# ADC12_3 register map
Vendor: Texas Instruments
Peripheral module from a debugger description file (folder msp430).
Registers are 16-bit, read-write, reset 0x0 unless marked. A register's access mark holds for its fields unless they carry their own. Offsets are as the file gives them; lines under a group give offsets from that group; [hi:lo] are bit positions; {n}, {i} and the like mark numbered series; 'fields as' and 'values as' point back to an identical list; <NAME> marks a mode.

## ADC12
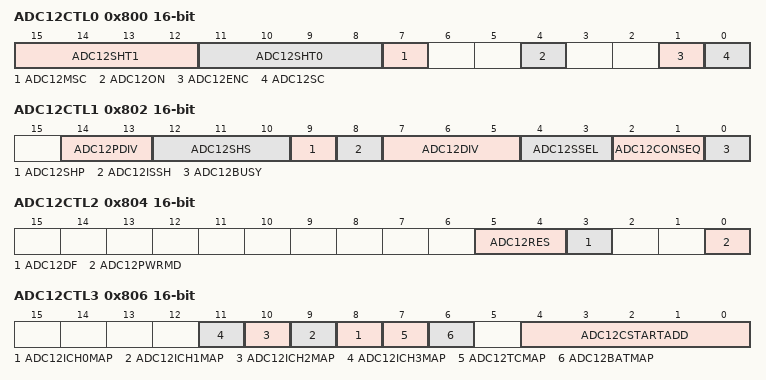
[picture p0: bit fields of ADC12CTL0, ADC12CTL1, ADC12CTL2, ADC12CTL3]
0x800 ADC12CTL0 — ADC12 B Control 0
  [15:12] ADC12SHT1 — ADC12 Sample Hold 1 Select Bit: 0
    {v}=ADC12 Sample Hold 1 Select Bit: {v} (v=0..15)
  [11:8] ADC12SHT0 — ADC12 Sample Hold 0 Select Bit: 0
    {v}=ADC12 Sample Hold 0 Select Bit: {v} (v=0..15)
  [7] ADC12MSC — ADC12 Multiple SampleConversion
  [4] ADC12ON — ADC12 On/enable
  [1] ADC12ENC — ADC12 Enable Conversion
  [0] ADC12SC — ADC12 Start Conversion
0x802 ADC12CTL1 — ADC12 B Control 1
  [14:13] ADC12PDIV — ADC12 Predivider Bit: 0
    {v}=ADC12 Clock predivider Select {v} (v=0..3)
  [12:10] ADC12SHS — ADC12 Sample/Hold Source Bit: 0
    {v}=ADC12 Sample/Hold Source: {v} (v=0..7)
  [9] ADC12SHP — ADC12 Sample/Hold Pulse Mode
  [8] ADC12ISSH — ADC12 Invert Sample Hold Signal
  [7:5] ADC12DIV — ADC12 Clock Divider Select Bit: 0
    {v}=ADC12 Clock Divider Select: {v} (v=0..7)
  [4:3] ADC12SSEL — ADC12 Clock Source Select Bit: 0
    {v}=ADC12 Clock Source Select: {v} (v=0..3)
  [2:1] ADC12CONSEQ — ADC12 Conversion Sequence Select Bit: 0
    {v}=ADC12 Conversion Sequence Select: {v} (v=0..3)
  [0] ADC12BUSY
0x804 ADC12CTL2 — ADC12 B Control 2
  [5:4] ADC12RES — ADC12 Resolution Bit: 0
    0=ADC12+ Resolution : 8 Bit; 1=ADC12+ Resolution : 10 Bit; 2=ADC12+ Resolution : 12 Bit; 3=ADC12+ Resolution : reserved
  [3] ADC12DF — ADC12 Data Format
  [0] ADC12PWRMD — ADC12 Power Mode
0x806 ADC12CTL3 — ADC12 B Control 3
  [n+8] ADC12ICH{n}MAP (n=0..3) — ADC12 Internal Channel {n} select
  [7] ADC12TCMAP — ADC12 Internal TempSensor select
  [6] ADC12BATMAP — ADC12 Internal AVCC/2 select
  [4:0] ADC12CSTARTADD — ADC12 Conversion Start Address Bit: 0
    {v}=ADC12 Conversion Start Address: {v} (v=0..31)
0x808 ADC12LO access not given reset not defined — ADC12 B Window Comparator High Threshold
0x80A ADC12HI access not given reset not defined — ADC12 B Window Comparator High Threshold
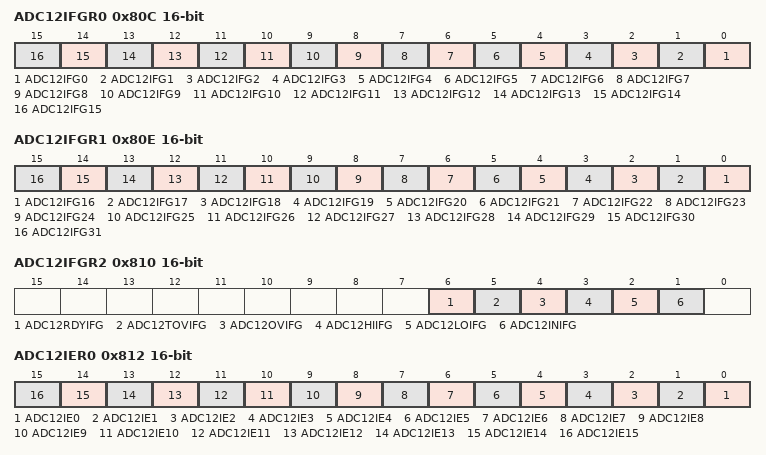
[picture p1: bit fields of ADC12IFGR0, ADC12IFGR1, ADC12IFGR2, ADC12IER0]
0x80C ADC12IFGR0 — ADC12 B Interrupt Flag 0
  [n] ADC12IFG{n} (n=0..15) — ADC12 Memory {n} Interrupt Flag
0x80E ADC12IFGR1 — ADC12 B Interrupt Flag 1
  [n-16] ADC12IFG{n} (n=16..31) — ADC12 Memory {n} Interrupt Flag
0x810 ADC12IFGR2 — ADC12 B Interrupt Flag 2
  [6] ADC12RDYIFG — ADC12 local buffered reference ready interrupt Flag
  [5] ADC12TOVIFG — ADC12 Timer Overflow interrupt Flag
  [4] ADC12OVIFG — ADC12 ADC12MEMx Overflow interrupt Flag
  [3] ADC12HIIFG — ADC12 Interrupt Flag for upper threshold of the Window comparator
  [2] ADC12LOIFG — ADC12 Interrupt Flag for lower threshold of the Window comparator
  [1] ADC12INIFG — ADC12 Interrupt Flag for the inside of window of the Window comparator
0x812 ADC12IER0 — ADC12 B Interrupt Enable 0
  [n] ADC12IE{n} (n=0..15) — ADC12 Memory {n} Interrupt Enable
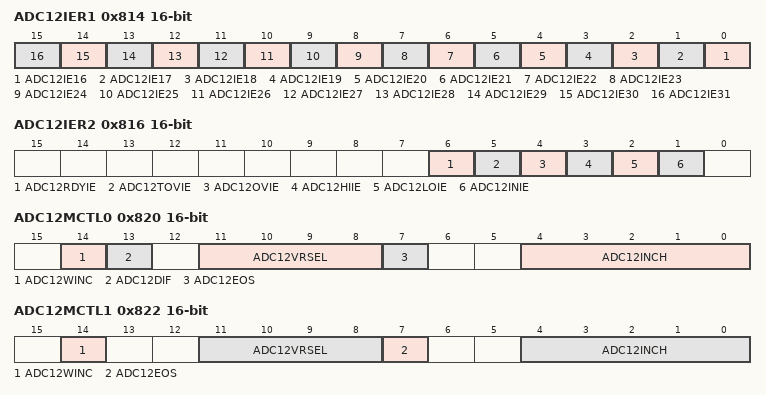
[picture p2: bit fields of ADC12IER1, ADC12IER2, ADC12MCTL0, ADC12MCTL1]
0x814 ADC12IER1 — ADC12 B Interrupt Enable 1
  [n-16] ADC12IE{n} (n=16..31) — ADC12 Memory {n} Interrupt Enable
0x816 ADC12IER2 — ADC12 B Interrupt Enable 2
  [6] ADC12RDYIE — ADC12 local buffered reference ready interrupt enable
  [5] ADC12TOVIE — ADC12 Timer Overflow interrupt enable
  [4] ADC12OVIE — ADC12 ADC12MEMx Overflow interrupt enable
  [3] ADC12HIIE — ADC12 Interrupt enable for upper threshold of the Window comparator
  [2] ADC12LOIE — ADC12 Interrupt enable for lower threshold of the Window comparator
  [1] ADC12INIE — ADC12 Interrupt enable for the inside of window of the Window comparator
0x818 ADC12IV access not given reset not defined — ADC12 B Interrupt Vector Word
0x820 ADC12MCTL0 — ADC12 Memory Control 0
  [14] ADC12WINC — ADC12 Comparator window enable
  [13] ADC12DIF — ADC12 Differential mode (only for even Registers)
  [11:8] ADC12VRSEL — ADC12 VR Select Bit 0
    {v}=ADC12 Select Reference {v} (v=0..15)
  [7] ADC12EOS — ADC12 End of Sequence
  [4:0] ADC12INCH — ADC12 Input Channel Select Bit 0
    {v}=ADC12 Input Channel {v} (v=0..31)
0x822 ADC12MCTL1 — ADC12 Memory Control 1
  [14] ADC12WINC — ADC12 Comparator window enable
  [11:8] ADC12VRSEL — ADC12 VR Select Bit 0
    {v}=ADC12 Select Reference {v} (v=0..15)
  [7] ADC12EOS — ADC12 End of Sequence
  [4:0] ADC12INCH — ADC12 Input Channel Select Bit 0
    {v}=ADC12 Input Channel {v} (v=0..31)
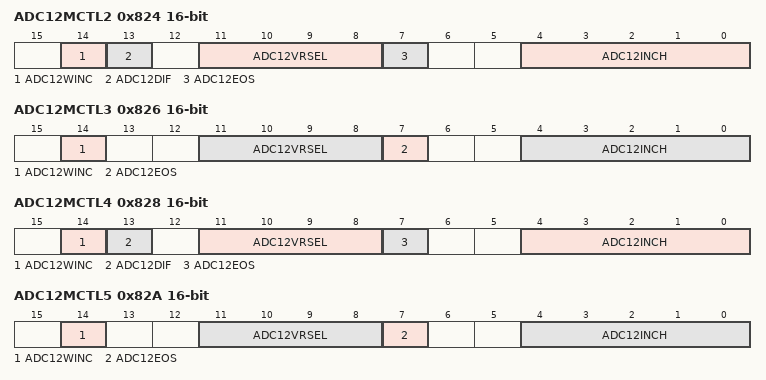
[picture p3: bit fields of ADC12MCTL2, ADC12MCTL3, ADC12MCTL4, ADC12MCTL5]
0x824 ADC12MCTL2 — ADC12 Memory Control 2
  fields as ADC12MCTL0
0x826 ADC12MCTL3 — ADC12 Memory Control 3
  fields as ADC12MCTL1
0x828 ADC12MCTL4 — ADC12 Memory Control 4
  fields as ADC12MCTL0
0x82A ADC12MCTL5 — ADC12 Memory Control 5
  fields as ADC12MCTL1
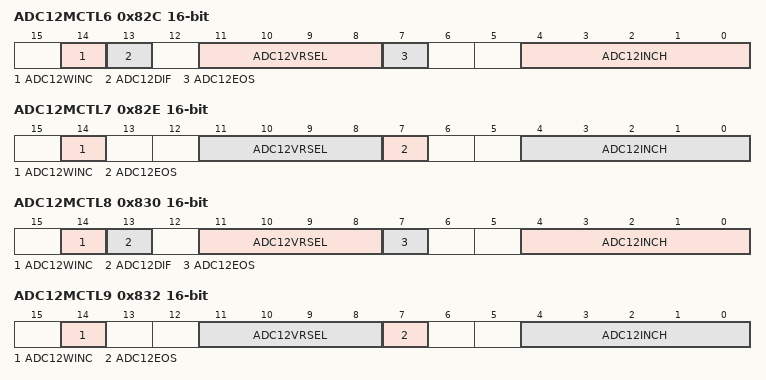
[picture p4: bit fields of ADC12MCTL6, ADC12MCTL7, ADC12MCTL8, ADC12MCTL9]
0x82C ADC12MCTL6 — ADC12 Memory Control 6
  fields as ADC12MCTL0
0x82E ADC12MCTL7 — ADC12 Memory Control 7
  fields as ADC12MCTL1
0x830 ADC12MCTL8 — ADC12 Memory Control 8
  fields as ADC12MCTL0
0x832 ADC12MCTL9 — ADC12 Memory Control 9
  fields as ADC12MCTL1
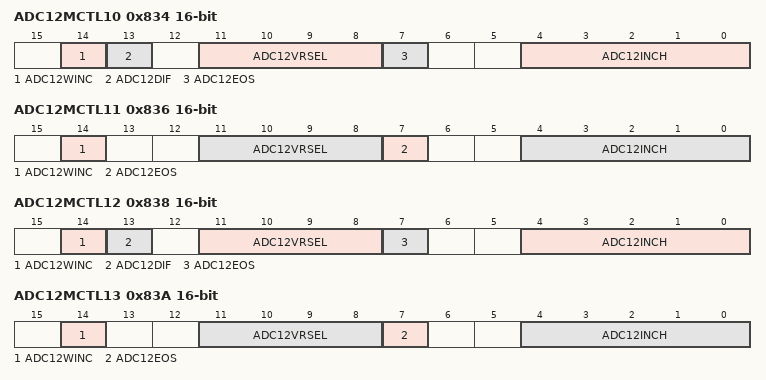
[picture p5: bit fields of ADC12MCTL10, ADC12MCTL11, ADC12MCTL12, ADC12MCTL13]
0x834 ADC12MCTL10 — ADC12 Memory Control 10
  fields as ADC12MCTL0
0x836 ADC12MCTL11 — ADC12 Memory Control 11
  fields as ADC12MCTL1
0x838 ADC12MCTL12 — ADC12 Memory Control 12
  fields as ADC12MCTL0
0x83A ADC12MCTL13 — ADC12 Memory Control 13
  fields as ADC12MCTL1
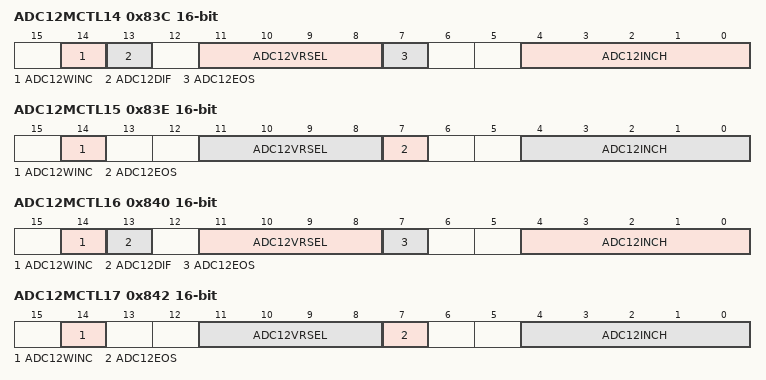
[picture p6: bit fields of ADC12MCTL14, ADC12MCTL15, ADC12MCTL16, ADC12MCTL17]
0x83C ADC12MCTL14 — ADC12 Memory Control 14
  fields as ADC12MCTL0
0x83E ADC12MCTL15 — ADC12 Memory Control 15
  fields as ADC12MCTL1
0x840 ADC12MCTL16 — ADC12 Memory Control 16
  fields as ADC12MCTL0
0x842 ADC12MCTL17 — ADC12 Memory Control 17
  fields as ADC12MCTL1
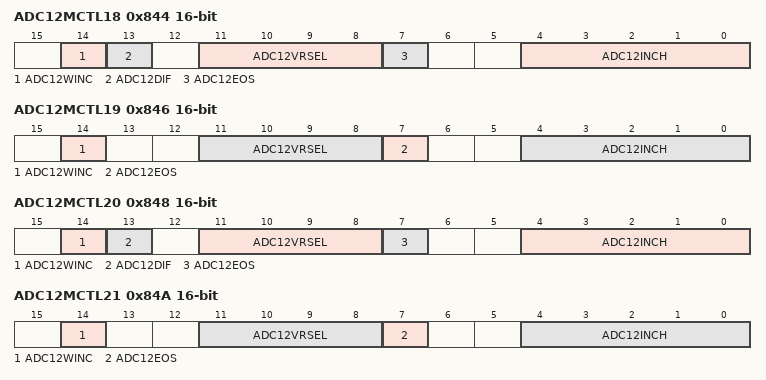
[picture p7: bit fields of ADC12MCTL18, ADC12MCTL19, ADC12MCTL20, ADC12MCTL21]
0x844 ADC12MCTL18 — ADC12 Memory Control 18
  fields as ADC12MCTL0
0x846 ADC12MCTL19 — ADC12 Memory Control 19
  fields as ADC12MCTL1
0x848 ADC12MCTL20 — ADC12 Memory Control 20
  fields as ADC12MCTL0
0x84A ADC12MCTL21 — ADC12 Memory Control 21
  fields as ADC12MCTL1
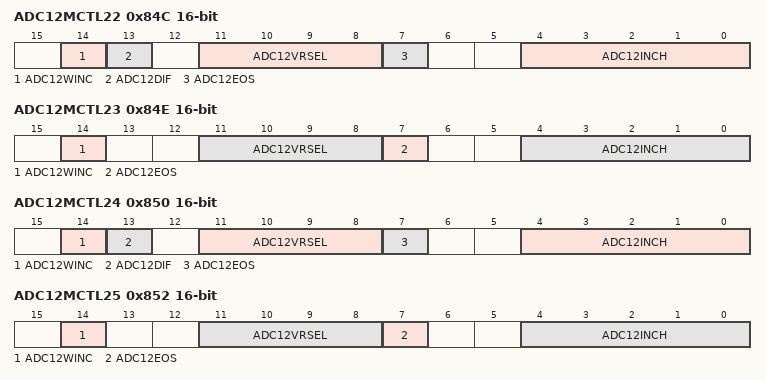
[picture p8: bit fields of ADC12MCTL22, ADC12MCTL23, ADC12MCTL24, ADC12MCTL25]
0x84C ADC12MCTL22 — ADC12 Memory Control 22
  fields as ADC12MCTL0
0x84E ADC12MCTL23 — ADC12 Memory Control 23
  fields as ADC12MCTL1
0x850 ADC12MCTL24 — ADC12 Memory Control 24
  fields as ADC12MCTL0
0x852 ADC12MCTL25 — ADC12 Memory Control 25
  fields as ADC12MCTL1
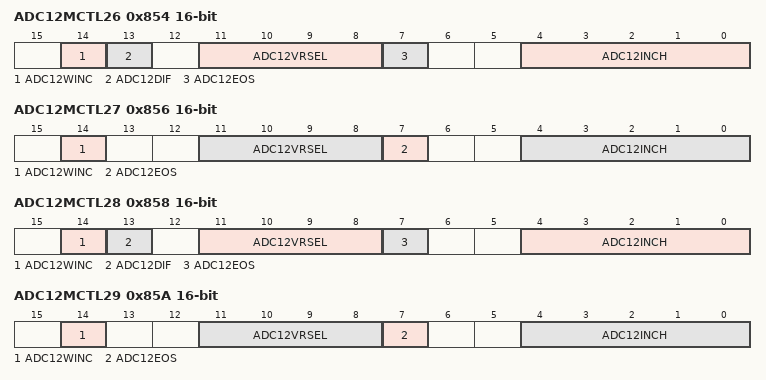
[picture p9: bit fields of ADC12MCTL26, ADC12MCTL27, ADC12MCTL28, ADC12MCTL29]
0x854 ADC12MCTL26 — ADC12 Memory Control 26
  fields as ADC12MCTL0
0x856 ADC12MCTL27 — ADC12 Memory Control 27
  fields as ADC12MCTL1
0x858 ADC12MCTL28 — ADC12 Memory Control 28
  fields as ADC12MCTL0
0x85A ADC12MCTL29 — ADC12 Memory Control 29
  fields as ADC12MCTL1
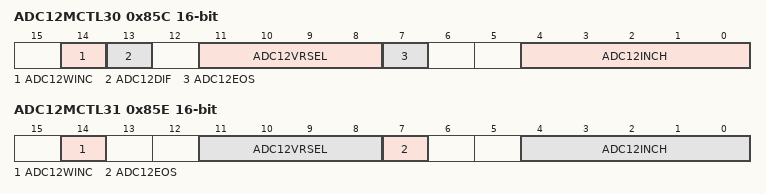
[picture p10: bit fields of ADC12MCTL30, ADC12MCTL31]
0x85C ADC12MCTL30 — ADC12 Memory Control 30
  fields as ADC12MCTL0
0x85E ADC12MCTL31 — ADC12 Memory Control 31
  fields as ADC12MCTL1
{0x860+2i} ADC12MEM{i} access not given reset not defined (i=0..31) — ADC12 Conversion Memory {i}
